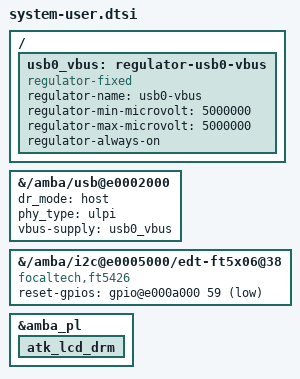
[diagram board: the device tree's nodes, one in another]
/include/ "system-conf.dtsi"
/ {
	usb0_vbus: regulator-usb0-vbus {
		compatible = "regulator-fixed";
		regulator-name = "usb0-vbus";
		regulator-min-microvolt = <5000000>;
		regulator-max-microvolt = <5000000>;
		regulator-always-on;
	};
};

&{/amba/usb@e0002000} {
	dr_mode = "host";
	phy_type = "ulpi";
	vbus-supply = <&usb0_vbus>;
};

&{/amba/i2c@e0005000/edt-ft5x06@38} {
	compatible = "focaltech,ft5426", "edt,edt-ft5406";
	/delete-property/ reset-gpio;
	/delete-property/ interrupt-gpio;
	reset-gpios = <&{/amba/gpio@e000a000} 59 1>;
};

&amba_pl {
	atk_lcd_drm {
		/* timing2 => 1024x600 */
	};
};
